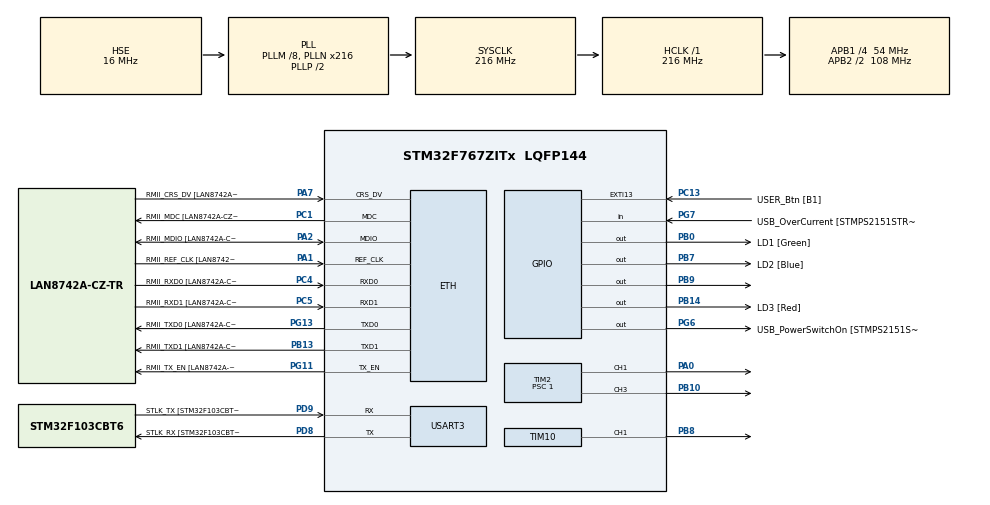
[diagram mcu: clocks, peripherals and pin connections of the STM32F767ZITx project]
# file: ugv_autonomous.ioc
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CORTEX_M7.AccessPermission-Cortex_Memory_Protection_Unit_Region0_Settings=MPU_REGION_FULL_ACCESS
CORTEX_M7.BaseAddress-Cortex_Memory_Protection_Unit_Region0_Settings=0x2007c000
CORTEX_M7.CPU_DCache=Enabled
CORTEX_M7.CPU_ICache=Enabled
CORTEX_M7.DisableExec-Cortex_Memory_Protection_Unit_Region0_Settings=MPU_INSTRUCTION_ACCESS_DISABLE
CORTEX_M7.Enable-Cortex_Memory_Protection_Unit_Region0_Settings=MPU_REGION_ENABLE
CORTEX_M7.IsShareable-Cortex_Memory_Protection_Unit_Region0_Settings=MPU_ACCESS_SHAREABLE
CORTEX_M7.MPU_Control=MPU_PRIVILEGED_DEFAULT
CORTEX_M7.PREFETCH_ENABLE=1
CORTEX_M7.Size-Cortex_Memory_Protection_Unit_Region0_Settings=MPU_REGION_SIZE_16KB
CORTEX_M7.TypeExtField-Cortex_Memory_Protection_Unit_Region0_Settings=MPU_TEX_LEVEL1
ETH.MACAddr=00\:80\:E1\:00\:00\:20
ETH.MediaInterface=HAL_ETH_RMII_MODE
LWIP.BSP.number=1
LWIP.GATEWAY_ADDRESS=192.168.020.001
LWIP.IP_ADDRESS=192.168.020.021
LWIP.LWIP_DHCP=0
LWIP.MEM_SIZE=10*1024
LWIP.NETMASK_ADDRESS=255.255.255.000
LWIP.Version=v2.1.2_Cube
LWIP0.BSP.STBoard=false
LWIP0.BSP.api=BSP_COMPONENT_DRIVER
LWIP0.BSP.component=LAN8742
LWIP0.BSP.instance=LAN8742
LWIP0.BSP.name=Driver_PHY
LWIP0.BSP.semaphore=S_LAN8742
LWIP0.BSP.solution=LAN8742
Mcu.Family=STM32F7
Mcu.Name=STM32F767ZITx
Mcu.Package=LQFP144
NVIC.ETH_IRQn=true\:0\:0\:false\:false\:true\:true\:true\:true
NVIC.PriorityGroup=NVIC_PRIORITYGROUP_4
NVIC.TIM1_BRK_TIM9_IRQn=true\:0\:0\:false\:false\:true\:true\:true\:true
NVIC.TIM1_UP_TIM10_IRQn=true\:0\:0\:false\:false\:true\:true\:true\:true
NVIC.TIM8_UP_TIM13_IRQn=true\:0\:0\:false\:false\:true\:true\:true\:true
PA0/WKUP.Signal=S_TIM2_CH1_ETR
PA1.GPIO_Label=RMII_REF_CLK [LAN8742A-CZ-TR_REFCLK0]
PA1.Mode=RMII
PA1.Signal=ETH_REF_CLK
PA10.GPIO_Label=USB_ID
PA10.Signal=USB_OTG_FS_ID
PA11.GPIO_Label=USB_DM
PA11.Signal=USB_OTG_FS_DM
PA12.GPIO_Label=USB_DP
PA12.Signal=USB_OTG_FS_DP
PA13.GPIO_Label=TMS
PA13.Signal=SYS_JTMS-SWDIO
PA14.GPIO_Label=TCK
PA14.Signal=SYS_JTCK-SWCLK
PA2.GPIO_Label=RMII_MDIO [LAN8742A-CZ-TR_MDIO]
PA2.Mode=RMII
PA2.Signal=ETH_MDIO
PA7.GPIO_Label=RMII_CRS_DV [LAN8742A-CZ-TR_CRS_DV]
PA7.Mode=RMII
PA7.Signal=ETH_CRS_DV
PA8.GPIO_Label=USB_SOF [TP1]
PA8.Signal=USB_OTG_FS_SOF
PA9.GPIO_Label=USB_VBUS
PA9.Signal=USB_OTG_FS_VBUS
PB0.GPIO_Label=LD1 [Green]
PB0.Signal=GPIO_Output
PB10.Signal=S_TIM2_CH3
PB13.GPIO_Label=RMII_TXD1 [LAN8742A-CZ-TR_TXD1]
PB13.Mode=RMII
PB13.Signal=ETH_TXD1
PB14.GPIO_Label=LD3 [Red]
PB14.Signal=GPIO_Output
PB3.GPIO_Label=SW0
PB3.Signal=SYS_JTDO-SWO
PB7.GPIO_Label=LD2 [Blue]
PB7.Signal=GPIO_Output
PB8.Signal=S_TIM10_CH1
PB9.Signal=GPIO_Output
PC1.GPIO_Label=RMII_MDC [LAN8742A-CZ-TR_MDC]
PC1.Mode=RMII
PC1.Signal=ETH_MDC
PC13.GPIO_Label=USER_Btn [B1]
PC13.Signal=GPXTI13
PC14/OSC32_IN.Signal=RCC_OSC32_IN
PC15/OSC32_OUT.Signal=RCC_OSC32_OUT
PC4.GPIO_Label=RMII_RXD0 [LAN8742A-CZ-TR_RXD0]
PC4.Mode=RMII
PC4.Signal=ETH_RXD0
PC5.GPIO_Label=RMII_RXD1 [LAN8742A-CZ-TR_RXD1]
PC5.Mode=RMII
PC5.Signal=ETH_RXD1
PD8.GPIO_Label=STLK_RX [STM32F103CBT6_PA3]
PD8.Mode=Asynchronous
PD8.Signal=USART3_TX
PD9.GPIO_Label=STLK_TX [STM32F103CBT6_PA2]
PD9.Mode=Asynchronous
PD9.Signal=USART3_RX
PG11.GPIO_Label=RMII_TX_EN [LAN8742A-CZ-TR_TXEN]
PG11.Mode=RMII
PG11.Signal=ETH_TX_EN
PG13.GPIO_Label=RMII_TXD0 [LAN8742A-CZ-TR_TXD0]
PG13.Mode=RMII
PG13.Signal=ETH_TXD0
PG6.GPIO_Label=USB_PowerSwitchOn [STMPS2151STR_EN]
PG6.Signal=GPIO_Output
PG7.GPIO_Label=USB_OverCurrent [STMPS2151STR_FAULT]
PG7.Signal=GPIO_Input
PH0/OSC_IN.GPIO_Label=MCO [STM32F103CBT6_PA8]
PH0/OSC_IN.Mode=HSE-External-Oscillator
PH0/OSC_IN.Signal=RCC_OSC_IN
PH1/OSC_OUT.Mode=HSE-External-Oscillator
PH1/OSC_OUT.Signal=RCC_OSC_OUT
ProjectManager.HeapSize=0x200
ProjectManager.StackSize=0x400
ProjectManager.TargetToolchain=STM32CubeIDE
RCC.48MHZClocksFreq_Value=24000000
RCC.AHBFreq_Value=216000000
RCC.APB1CLKDivider=RCC_HCLK_DIV4
RCC.APB1Freq_Value=54000000
RCC.APB1TimFreq_Value=108000000
RCC.APB2CLKDivider=RCC_HCLK_DIV2
RCC.APB2Freq_Value=108000000
RCC.APB2TimFreq_Value=216000000
RCC.CortexFreq_Value=216000000
RCC.HCLKFreq_Value=216000000
RCC.HSE_VALUE=16000000
RCC.HSI_VALUE=16000000
RCC.LSE_VALUE=32768
RCC.PLLM=8
RCC.PLLMUL=RCC_PLL_MUL9
RCC.PLLN=216
RCC.PLLSourceVirtual=RCC_PLLSOURCE_HSE
RCC.PRESCALERUSB=RCC_USBCLKSOURCE_PLL_DIV1_5
RCC.SYSCLKFreq_VALUE=216000000
RCC.SYSCLKSource=RCC_SYSCLKSOURCE_PLLCLK
RCC.SYSCLKSourceVirtual=RCC_SYSCLKSOURCE_PLLCLK
RCC.USBFreq_Value=216000000
RCC.VCOOutputFreq_Value=432000000
SH.S_TIM10_CH1.0=TIM10_CH1,PWM Generation1 CH1
SH.S_TIM2_CH1_ETR.0=TIM2_CH1,PWM Generation1 CH1
SH.S_TIM2_CH3.0=TIM2_CH3,PWM Generation3 CH3
TIM1.Period=10000
TIM1.Prescaler=10800
TIM10.AutoReloadPreload=TIM_AUTORELOAD_PRELOAD_ENABLE
TIM10.Channel=TIM_CHANNEL_1
TIM10.Period=29999
TIM10.Prescaler=71
TIM13.Period=499
TIM13.Prescaler=2700
TIM2.Channel-PWM\ Generation1\ CH1=TIM_CHANNEL_1
TIM2.Channel-PWM\ Generation3\ CH3=TIM_CHANNEL_3
TIM2.Period=32767
TIM2.Prescaler=1
USART3.VirtualMode-Asynchronous=VM_ASYNC
VP_LWIP_VS_Enabled.Mode=Enabled
VP_TIM10_VS_ClockSourceINT.Mode=Enable_Timer
VP_TIM13_VS_ClockSourceINT.Mode=Enable_Timer
VP_TIM1_VS_ClockSourceINT.Mode=Internal
board=NUCLEO-F767ZI

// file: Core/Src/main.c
/* USER CODE BEGIN Header */
/**
  ******************************************************************************
  * @file           : main.c
  * @brief          : Main program body
  ******************************************************************************
  * @attention
  *
  * Copyright (c) 2024 STMicroelectronics.
  * All rights reserved.
  *
  * This software is licensed under terms that can be found in the LICENSE file
  * in the root directory of this software component.
  * If no LICENSE file comes with this software, it is provided AS-IS.
  *
  ******************************************************************************
  */
/* USER CODE END Header */
#include "main.h"
#include "lwip.h"

/* USER CODE BEGIN Includes */
#include "lwip/pbuf.h"
#include "lwip/udp.h"
#include "lwip/tcp.h"

#include "stdio.h"
#include "string.h"

#include "ugv_servo.h"  //Include header for servo driver
#include "motor_control.h" // Motor Control Header for 2023 Driver

/* USER CODE END Includes */

/* USER CODE BEGIN PD */
#define MAX_DUTY 32767

/* USER CODE END PD */

TIM_HandleTypeDef htim1;
TIM_HandleTypeDef htim2;
TIM_HandleTypeDef htim10;
TIM_HandleTypeDef htim13;

UART_HandleTypeDef huart3;

/* USER CODE BEGIN PV */

// instantiate steering servo struct
ugvServo_t steeringServo;
MotorControl ugv_drive_mtr;
// Variable to control steering angle
float steer_val = 0;
float velocity_val = 0;
float heading_error = 0;

extern struct netif gnetif;
struct udp_pcb *upcb;
char buffer[100];
int counter;

/* USER CODE END PV */

void SystemClock_Config(void);
static void MPU_Config(void);
static void MX_GPIO_Init(void);
static void MX_TIM1_Init(void);
static void MX_TIM10_Init(void);
static void MX_USART3_UART_Init(void);
static void MX_TIM2_Init(void);
static void MX_TIM13_Init(void);
/* USER CODE BEGIN PFP */

void udp_receive_callback(void *arg, struct udp_pcb *upcb, struct pbuf *p,
		const ip_addr_t *addr, u16_t port);
static void udp_client_send();

void udp_client_connect();

void HAL_TIM_PeriodElapsedCallback(TIM_HandleTypeDef *htim);

/* USER CODE END PFP */

int main(void)
{

  /* MPU Configuration--------------------------------------------------------*/
  MPU_Config();
/* Enable the CPU Cache */

  /* Enable I-Cache---------------------------------------------------------*/
  SCB_EnableICache();

  /* Enable D-Cache---------------------------------------------------------*/
  SCB_EnableDCache();

  /* MCU Configuration--------------------------------------------------------*/

  /* Reset of all peripherals, Initializes the Flash interface and the Systick. */
  HAL_Init();

  /* Configure the system clock */
  SystemClock_Config();

  /* Initialize all configured peripherals */
  MX_GPIO_Init();
  MX_LWIP_Init();
  MX_TIM1_Init();
  MX_TIM10_Init();
  MX_USART3_UART_Init();
  MX_TIM2_Init();
  MX_TIM13_Init();
  /* USER CODE BEGIN 2 */

  // 2022 Servo Driver
	steeringServo.timerInstance = &htim10;
	steeringServo.timerCCRX = &TIM10->CCR1;
	steeringServo.timerCh = TIM_CHANNEL_1;

	/* Last Year's Steering Servo */
	/*
	steeringServo.timerARR = 59999;
	steeringServo.minPulse = 500;
	steeringServo.maxPulse = 2500;
	steeringServo.timerPeriod = 20000;
	steeringServo.travelAngle = 270.0;
	steeringServo.minLimit = 10.0;
	steeringServo.maxLimit = 260.0;
	//	steeringServo.travelOffset = 125.0;
	//	steeringServo.travelOffset = 50;
	steeringServo.travelOffset = 10;
	*/

	// 2022 Servo Driver
	  steeringServo.timerInstance = &htim10;
	  steeringServo.timerCCRX = &TIM10->CCR1;
	  steeringServo.timerCh = TIM_CHANNEL_1;
	  steeringServo.timerARR = htim10.Init.Period;
	  steeringServo.minPulse = 500;
	  steeringServo.maxPulse = 2500;
	  steeringServo.timerPeriod = 20000;
	  steeringServo.travelAngle = 270.0;

	  steeringServo.minLimit = 0.0;
	  steeringServo.maxLimit = 105.0;

	  steeringServo.travelOffset = 50;

	ugv_servoInitServo(&steeringServo);
	MotorControl_Init(&ugv_drive_mtr, &htim2, TIM_CHANNEL_1, TIM_CHANNEL_3);

  udp_client_connect();

  /* Start HAL timer interrupt
  /  Interrupt occurs once every 50ms
  */
  HAL_TIM_Base_Start_IT(&htim13);

  /* USER CODE END 2 */

  /* Infinite loop */
  /* USER CODE BEGIN WHILE */
  while (1)
  {

	  ethernetif_input(&gnetif);
	  ethernet_link_check_state(&gnetif);
	  //udpClient
//	  gnetif.input()
	  //ethernet_input(p, netif)
	  sys_check_timeouts();
    /* USER CODE END WHILE */

  }
}

void SystemClock_Config(void)
{
  RCC_OscInitTypeDef RCC_OscInitStruct = {0};
  RCC_ClkInitTypeDef RCC_ClkInitStruct = {0};

  /** Configure the main internal regulator output voltage
  */
  __HAL_RCC_PWR_CLK_ENABLE();
  __HAL_PWR_VOLTAGESCALING_CONFIG(PWR_REGULATOR_VOLTAGE_SCALE1);

  /** Initializes the RCC Oscillators according to the specified parameters
  * in the RCC_OscInitTypeDef structure.
  */
  RCC_OscInitStruct.OscillatorType = RCC_OSCILLATORTYPE_HSE;
  RCC_OscInitStruct.HSEState = RCC_HSE_ON;
  RCC_OscInitStruct.PLL.PLLState = RCC_PLL_ON;
  RCC_OscInitStruct.PLL.PLLSource = RCC_PLLSOURCE_HSE;
  RCC_OscInitStruct.PLL.PLLM = 8;
  RCC_OscInitStruct.PLL.PLLN = 216;
  RCC_OscInitStruct.PLL.PLLP = RCC_PLLP_DIV2;
  RCC_OscInitStruct.PLL.PLLQ = 2;
  RCC_OscInitStruct.PLL.PLLR = 2;
  if (HAL_RCC_OscConfig(&RCC_OscInitStruct) != HAL_OK)
  {
    Error_Handler();
  }

  /** Activate the Over-Drive mode
  */
  if (HAL_PWREx_EnableOverDrive() != HAL_OK)
  {
    Error_Handler();
  }

  /** Initializes the CPU, AHB and APB buses clocks
  */
  RCC_ClkInitStruct.ClockType = RCC_CLOCKTYPE_HCLK|RCC_CLOCKTYPE_SYSCLK
                              |RCC_CLOCKTYPE_PCLK1|RCC_CLOCKTYPE_PCLK2;
  RCC_ClkInitStruct.SYSCLKSource = RCC_SYSCLKSOURCE_PLLCLK;
  RCC_ClkInitStruct.AHBCLKDivider = RCC_SYSCLK_DIV1;
  RCC_ClkInitStruct.APB1CLKDivider = RCC_HCLK_DIV4;
  RCC_ClkInitStruct.APB2CLKDivider = RCC_HCLK_DIV2;

  if (HAL_RCC_ClockConfig(&RCC_ClkInitStruct, FLASH_LATENCY_7) != HAL_OK)
  {
    Error_Handler();
  }
}

static void MX_TIM1_Init(void)
{

  TIM_ClockConfigTypeDef sClockSourceConfig = {0};
  TIM_MasterConfigTypeDef sMasterConfig = {0};

  htim1.Instance = TIM1;
  htim1.Init.Prescaler = 10800;
  htim1.Init.CounterMode = TIM_COUNTERMODE_UP;
  htim1.Init.Period = 10000;
  htim1.Init.ClockDivision = TIM_CLOCKDIVISION_DIV1;
  htim1.Init.RepetitionCounter = 0;
  htim1.Init.AutoReloadPreload = TIM_AUTORELOAD_PRELOAD_DISABLE;
  if (HAL_TIM_Base_Init(&htim1) != HAL_OK)
  {
    Error_Handler();
  }
  sClockSourceConfig.ClockSource = TIM_CLOCKSOURCE_INTERNAL;
  if (HAL_TIM_ConfigClockSource(&htim1, &sClockSourceConfig) != HAL_OK)
  {
    Error_Handler();
  }
  sMasterConfig.MasterOutputTrigger = TIM_TRGO_RESET;
  sMasterConfig.MasterOutputTrigger2 = TIM_TRGO2_RESET;
  sMasterConfig.MasterSlaveMode = TIM_MASTERSLAVEMODE_DISABLE;
  if (HAL_TIMEx_MasterConfigSynchronization(&htim1, &sMasterConfig) != HAL_OK)
  {
    Error_Handler();
  }

}

static void MX_TIM2_Init(void)
{

  TIM_MasterConfigTypeDef sMasterConfig = {0};
  TIM_OC_InitTypeDef sConfigOC = {0};

  htim2.Instance = TIM2;
  htim2.Init.Prescaler = 1;
  htim2.Init.CounterMode = TIM_COUNTERMODE_UP;
  htim2.Init.Period = 32767;
  htim2.Init.ClockDivision = TIM_CLOCKDIVISION_DIV1;
  htim2.Init.AutoReloadPreload = TIM_AUTORELOAD_PRELOAD_DISABLE;
  if (HAL_TIM_PWM_Init(&htim2) != HAL_OK)
  {
    Error_Handler();
  }
  sMasterConfig.MasterOutputTrigger = TIM_TRGO_RESET;
  sMasterConfig.MasterSlaveMode = TIM_MASTERSLAVEMODE_DISABLE;
  if (HAL_TIMEx_MasterConfigSynchronization(&htim2, &sMasterConfig) != HAL_OK)
  {
    Error_Handler();
  }
  sConfigOC.OCMode = TIM_OCMODE_PWM1;
  sConfigOC.Pulse = 0;
  sConfigOC.OCPolarity = TIM_OCPOLARITY_HIGH;
  sConfigOC.OCFastMode = TIM_OCFAST_DISABLE;
  if (HAL_TIM_PWM_ConfigChannel(&htim2, &sConfigOC, TIM_CHANNEL_1) != HAL_OK)
  {
    Error_Handler();
  }
  if (HAL_TIM_PWM_ConfigChannel(&htim2, &sConfigOC, TIM_CHANNEL_3) != HAL_OK)
  {
    Error_Handler();
  }
  HAL_TIM_MspPostInit(&htim2);

}

static void MX_TIM10_Init(void)
{

  TIM_OC_InitTypeDef sConfigOC = {0};

  htim10.Instance = TIM10;
  htim10.Init.Prescaler = 71;
  htim10.Init.CounterMode = TIM_COUNTERMODE_UP;
  htim10.Init.Period = 29999;
  htim10.Init.ClockDivision = TIM_CLOCKDIVISION_DIV1;
  htim10.Init.AutoReloadPreload = TIM_AUTORELOAD_PRELOAD_ENABLE;
  if (HAL_TIM_Base_Init(&htim10) != HAL_OK)
  {
    Error_Handler();
  }
  if (HAL_TIM_PWM_Init(&htim10) != HAL_OK)
  {
    Error_Handler();
  }
  sConfigOC.OCMode = TIM_OCMODE_PWM1;
  sConfigOC.Pulse = 0;
  sConfigOC.OCPolarity = TIM_OCPOLARITY_HIGH;
  sConfigOC.OCFastMode = TIM_OCFAST_DISABLE;
  if (HAL_TIM_PWM_ConfigChannel(&htim10, &sConfigOC, TIM_CHANNEL_1) != HAL_OK)
  {
    Error_Handler();
  }
  HAL_TIM_MspPostInit(&htim10);

}

static void MX_TIM13_Init(void)
{

  htim13.Instance = TIM13;
  htim13.Init.Prescaler = 2700;
  htim13.Init.CounterMode = TIM_COUNTERMODE_UP;
  htim13.Init.Period = 499;
  htim13.Init.ClockDivision = TIM_CLOCKDIVISION_DIV1;
  htim13.Init.AutoReloadPreload = TIM_AUTORELOAD_PRELOAD_DISABLE;
  if (HAL_TIM_Base_Init(&htim13) != HAL_OK)
  {
    Error_Handler();
  }

}

static void MX_USART3_UART_Init(void)
{

  huart3.Instance = USART3;
  huart3.Init.BaudRate = 115200;
  huart3.Init.WordLength = UART_WORDLENGTH_8B;
  huart3.Init.StopBits = UART_STOPBITS_1;
  huart3.Init.Parity = UART_PARITY_NONE;
  huart3.Init.Mode = UART_MODE_TX_RX;
  huart3.Init.HwFlowCtl = UART_HWCONTROL_NONE;
  huart3.Init.OverSampling = UART_OVERSAMPLING_16;
  huart3.Init.OneBitSampling = UART_ONE_BIT_SAMPLE_DISABLE;
  huart3.AdvancedInit.AdvFeatureInit = UART_ADVFEATURE_NO_INIT;
  if (HAL_UART_Init(&huart3) != HAL_OK)
  {
    Error_Handler();
  }

}

static void MX_GPIO_Init(void)
{
  GPIO_InitTypeDef GPIO_InitStruct = {0};

  /* GPIO Ports Clock Enable */
  __HAL_RCC_GPIOC_CLK_ENABLE();
  __HAL_RCC_GPIOH_CLK_ENABLE();
  __HAL_RCC_GPIOA_CLK_ENABLE();
  __HAL_RCC_GPIOB_CLK_ENABLE();
  __HAL_RCC_GPIOD_CLK_ENABLE();
  __HAL_RCC_GPIOG_CLK_ENABLE();

  /*Configure GPIO pin Output Level */
  HAL_GPIO_WritePin(GPIOB, LD1_Pin|LD3_Pin|LD2_Pin|GPIO_PIN_9, GPIO_PIN_RESET);

  /*Configure GPIO pin Output Level */
  HAL_GPIO_WritePin(USB_PowerSwitchOn_GPIO_Port, USB_PowerSwitchOn_Pin, GPIO_PIN_RESET);

  /*Configure GPIO pin : USER_Btn_Pin */
  GPIO_InitStruct.Pin = USER_Btn_Pin;
  GPIO_InitStruct.Mode = GPIO_MODE_IT_RISING;
  GPIO_InitStruct.Pull = GPIO_NOPULL;
  HAL_GPIO_Init(USER_Btn_GPIO_Port, &GPIO_InitStruct);

  /*Configure GPIO pins : LD1_Pin LD3_Pin LD2_Pin PB9 */
  GPIO_InitStruct.Pin = LD1_Pin|LD3_Pin|LD2_Pin|GPIO_PIN_9;
  GPIO_InitStruct.Mode = GPIO_MODE_OUTPUT_PP;
  GPIO_InitStruct.Pull = GPIO_NOPULL;
  GPIO_InitStruct.Speed = GPIO_SPEED_FREQ_LOW;
  HAL_GPIO_Init(GPIOB, &GPIO_InitStruct);

  /*Configure GPIO pin : USB_PowerSwitchOn_Pin */
  GPIO_InitStruct.Pin = USB_PowerSwitchOn_Pin;
  GPIO_InitStruct.Mode = GPIO_MODE_OUTPUT_PP;
  GPIO_InitStruct.Pull = GPIO_NOPULL;
  GPIO_InitStruct.Speed = GPIO_SPEED_FREQ_LOW;
  HAL_GPIO_Init(USB_PowerSwitchOn_GPIO_Port, &GPIO_InitStruct);

  /*Configure GPIO pin : USB_OverCurrent_Pin */
  GPIO_InitStruct.Pin = USB_OverCurrent_Pin;
  GPIO_InitStruct.Mode = GPIO_MODE_INPUT;
  GPIO_InitStruct.Pull = GPIO_NOPULL;
  HAL_GPIO_Init(USB_OverCurrent_GPIO_Port, &GPIO_InitStruct);

  /*Configure GPIO pins : USB_SOF_Pin USB_ID_Pin USB_DM_Pin USB_DP_Pin */
  GPIO_InitStruct.Pin = USB_SOF_Pin|USB_ID_Pin|USB_DM_Pin|USB_DP_Pin;
  GPIO_InitStruct.Mode = GPIO_MODE_AF_PP;
  GPIO_InitStruct.Pull = GPIO_NOPULL;
  GPIO_InitStruct.Speed = GPIO_SPEED_FREQ_VERY_HIGH;
  GPIO_InitStruct.Alternate = GPIO_AF10_OTG_FS;
  HAL_GPIO_Init(GPIOA, &GPIO_InitStruct);

  /*Configure GPIO pin : USB_VBUS_Pin */
  GPIO_InitStruct.Pin = USB_VBUS_Pin;
  GPIO_InitStruct.Mode = GPIO_MODE_INPUT;
  GPIO_InitStruct.Pull = GPIO_NOPULL;
  HAL_GPIO_Init(USB_VBUS_GPIO_Port, &GPIO_InitStruct);

}

/* USER CODE BEGIN 4 */

/*
 * The timer callback is executing the heading control loop every T = $(50ms)
 *
 */

void HAL_TIM_PeriodElapsedCallback(TIM_HandleTypeDef *htim)
{
	HAL_GPIO_TogglePin(GPIOB, GPIO_PIN_14);
	HAL_GPIO_TogglePin(GPIOB, GPIO_PIN_9);

	static const float Kp_heading = 1.5;  //Kp value for heading controller

	steer_val =  Kp_heading * heading_error;
	ugv_servoSetAngle(&steeringServo, steeringServo.maxLimit *steer_val + 0.224*steeringServo.maxLimit);
	MotorControl_SetSpeed(&ugv_drive_mtr, &htim2, velocity_val);

	// Timer callback meant to send data from stm -> Rpi in a periodic manner

//	udp_client_send();
}

void udp_client_connect()
{
	err_t err;

	// Create a new UDP control block
	// Need to check for null return
	upcb = udp_new();

	// Bind control block to module's IP address and port
	// Static IP address: 192.168.2.xxx
	ip_addr_t my_ip;
//	IP_ADDR4(&my_ip, 192, 168, 5, 21); 	//STM ip when connected to RPI 5
	IP_ADDR4(&my_ip, 192, 168, 20, 21); //STM ip when connected to Jetson Orin
//	IP_ADDR4(&my_ip, 192, 168, 2, 21); 	// STM ip when connected to linux desktop

	// Binds udp protocol control block to a local IP address
	// Arbitrary port # selection: 8
	udp_bind(upcb, &my_ip, 8);

	// Configure destination IP address
	// Host ip address: 192.168.2.5
	// Arbitrary port # selection: 12345
	ip_addr_t DestIPaddr;
//	IP_ADDR4(&DestIPaddr, 192, 168, 5, 5);  //RPI 5 host ip address
	IP_ADDR4(&DestIPaddr, 192, 168, 20, 5);  //Jetson Orin Nano host ip address
//	IP_ADDR4(&DestIPaddr, 192, 168, 2, 5);  //Desktop Host ip address
	err = udp_connect(upcb, &DestIPaddr, 12345);

	if (err == HAL_OK)
	{
		// Blue LED
		HAL_GPIO_TogglePin(GPIOB, GPIO_PIN_7);
		// Set a receive callback for the upcb when server sends data to client
		udp_recv(upcb, udp_receive_callback, NULL);

	}
}

static void udp_client_send()
{
	struct pbuf *tx_buff;
	char data[100];

	int len = sprintf(data, "Sending UDP client message: %d", counter);

	// Allocate pbuf from pool
	tx_buff = pbuf_alloc(PBUF_TRANSPORT, len, PBUF_RAM);

	if (tx_buff != NULL)
	{
		// Copy data into pbuf
		pbuf_take(tx_buff, data, len);

		// Send udp data
		udp_send(upcb, tx_buff);

		// Free pbuf
		pbuf_free(tx_buff);
	}
}

void udp_receive_callback(void *arg, struct udp_pcb *upcb, struct pbuf *p,
		const ip_addr_t *addr, u16_t port)
{
	// Copy data from the pbuf
	strncpy(buffer, (char *)p->payload, p->len);

	//Parse Input
	uint8_t data_index = 0;
	float drive_vals[10] = {0};
	char *buffer_data = strtok(buffer, ",");
	while (buffer_data != NULL && data_index < 10)
	{
		float conv_check = atof(buffer_data);
		//Make data was converted properly
		if (conv_check == 0)
		{
			HAL_GPIO_TogglePin(GPIOB, GPIO_PIN_14);
		}

		drive_vals[data_index] = conv_check;

		++data_index;
		buffer_data = strtok(NULL, ",");
	}

	// Free recieve pbuf;
	pbuf_free(p);

	velocity_val = drive_vals[0];
	//steer_val = drive_vals[1];
	heading_error = drive_vals[2]; //Receive Heading Error

	//Might need to reset drive_vals to 0
	// Set Steering Angle for Servo
//	ugv_servoSetAngle(&steeringServo, steeringServo.maxLimit *steer_val + 0.224*steeringServo.maxLimit);
//	//ugv_servoSetAngle(&steeringServo, drive_vals[1]);
//	MotorControl_SetSpeed(&ugv_drive_mtr, &htim2, velocity_val);

	HAL_GPIO_TogglePin(GPIOB, GPIO_PIN_0);
}

/* USER CODE END 4 */

/* MPU Configuration */

void MPU_Config(void)
{
  MPU_Region_InitTypeDef MPU_InitStruct = {0};

  /* Disables the MPU */
  HAL_MPU_Disable();

  /** Initializes and configures the Region and the memory to be protected
  */
  MPU_InitStruct.Enable = MPU_REGION_ENABLE;
  MPU_InitStruct.Number = MPU_REGION_NUMBER0;
  MPU_InitStruct.BaseAddress = 0x2007c000;
  MPU_InitStruct.Size = MPU_REGION_SIZE_16KB;
  MPU_InitStruct.SubRegionDisable = 0x0;
  MPU_InitStruct.TypeExtField = MPU_TEX_LEVEL1;
  MPU_InitStruct.AccessPermission = MPU_REGION_FULL_ACCESS;
  MPU_InitStruct.DisableExec = MPU_INSTRUCTION_ACCESS_DISABLE;
  MPU_InitStruct.IsShareable = MPU_ACCESS_SHAREABLE;
  MPU_InitStruct.IsCacheable = MPU_ACCESS_NOT_CACHEABLE;
  MPU_InitStruct.IsBufferable = MPU_ACCESS_NOT_BUFFERABLE;

  HAL_MPU_ConfigRegion(&MPU_InitStruct);
  /* Enables the MPU */
  HAL_MPU_Enable(MPU_PRIVILEGED_DEFAULT);

}

void Error_Handler(void)
{
  __disable_irq();
  while (1)
  {
  }
}
